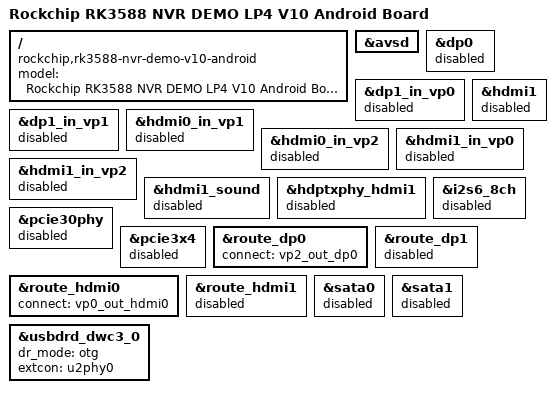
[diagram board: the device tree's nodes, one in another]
// SPDX-License-Identifier: (GPL-2.0+ OR MIT)
/*
 * Copyright (c) 2021 Rockchip Electronics Co., Ltd.
 *
 */

/dts-v1/;

#include "rk3588-nvr-demo.dtsi"
#include "rk3588-android.dtsi"

/ {
	model = "Rockchip RK3588 NVR DEMO LP4 V10 Android Board";
	compatible = "rockchip,rk3588-nvr-demo-v10-android", "rockchip,rk3588";
};

&avsd {
	status = "okay";
};

&dp0 {
	status = "disabled";
};

&dp1_in_vp0 {
	status = "disabled";
};

&dp1_in_vp1 {
	status = "disabled";
};

&hdmi0_in_vp1 {
	status = "disabled";
};

&hdmi0_in_vp2 {
	status = "disabled";
};

&hdmi1 {
	status = "disabled";
};

&hdmi1_in_vp0 {
	status = "disabled";
};

&hdmi1_in_vp2 {
	status = "disabled";
};

&hdmi1_sound {
	status = "disabled";
};

&hdptxphy_hdmi1 {
	status = "disabled";
};

&i2s6_8ch {
	status = "disabled";
};

&pcie30phy {
	status = "disabled";
};

&pcie3x4 {
	status = "disabled";
};

&route_dp0 {
	status = "okay";
	connect = <&vp2_out_dp0>;
	/delete-property/ force-output;
	/delete-node/ force_timing;
};

&route_dp1 {
	status = "disabled";
};

&route_hdmi0 {
	status = "okay";
	connect = <&vp0_out_hdmi0>;
	/delete-property/ force-output;
	/delete-node/ force_timing;
};

&route_hdmi1 {
	status = "disabled";
};

&sata0 {
	status = "disabled";
};

&sata1 {
	status = "disabled";
};

&usbdrd_dwc3_0 {
	dr_mode = "otg";
	extcon = <&u2phy0>;
	status = "okay";
};
